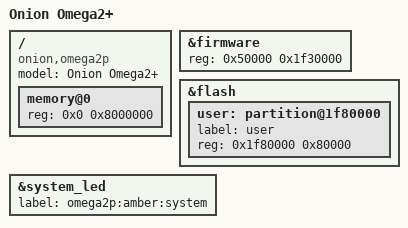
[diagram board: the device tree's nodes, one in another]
/dts-v1/;

#include "OMEGA2.dtsi"

/ {
	compatible = "onion,omega2p", "onion,omega2", "mediatek,mt7628an-soc";
	model = "Onion Omega2+";

	memory@0 {
		device_type = "memory";
		reg = <0x0 0x8000000>;
	};
};

&firmware {
	reg = <0x50000 0x1f30000>;
};

&flash {
	user: partition@1f80000 {
		label = "user";
		reg = <0x1f80000 0x80000>;
	};
};

&system_led {
	label = "omega2p:amber:system";
};
